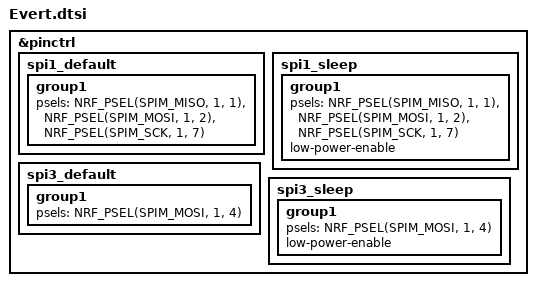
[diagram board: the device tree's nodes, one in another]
/*
 * Copyright (c) 2022 The ZMK Contributors
 * SPDX-License-Identifier: MIT
 */

&pinctrl {
    spi1_default: spi1_default {
        group1 {
            psels = <NRF_PSEL(SPIM_MISO, 1, 1)>,
                    <NRF_PSEL(SPIM_MOSI, 1, 2)>,
                    <NRF_PSEL(SPIM_SCK,  1, 7)>;
        };
    };

    spi1_sleep: spi1_sleep {
        group1 {
            psels = <NRF_PSEL(SPIM_MISO, 1, 1)>,
                    <NRF_PSEL(SPIM_MOSI, 1, 2)>,
                    <NRF_PSEL(SPIM_SCK,  1, 7)>;
            low-power-enable;
        };
    };

    spi3_default: spi3_default {
        group1 {
            psels = <NRF_PSEL(SPIM_MOSI, 1, 4)>;
        };
    };

    spi3_sleep: spi3_sleep {
        group1 {
            psels = <NRF_PSEL(SPIM_MOSI, 1, 4)>;
            low-power-enable;
        };
    };
};
